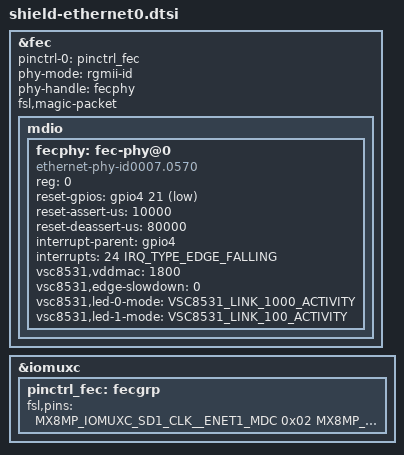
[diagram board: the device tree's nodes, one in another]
// SPDX-License-Identifier: (GPL-2.0+ OR MIT)
/*
 * Copyright 2025 CriticalShift
 */

#include <dt-bindings/net/mscc-phy-vsc8531.h>

&fec {
	pinctrl-names = "default";
	pinctrl-0 = <&pinctrl_fec>;
	phy-mode = "rgmii-id";
	phy-handle = <&fecphy>;
	fsl,magic-packet;
	status = "okay";

	mdio {
		#address-cells = <1>;
		#size-cells = <0>;

		fecphy: fec-phy@0 {
			compatible = "ethernet-phy-id0007.0570", "ethernet-phy-ieee802.3-c22";
			reg = <0>;

			/* Reset handler */
			reset-gpios = <&gpio4 21 GPIO_ACTIVE_LOW>;
			reset-assert-us = <10000>;
			reset-deassert-us = <80000>;

			/* Interrupt handler */
			interrupt-parent = <&gpio4>;
			interrupts = <24 IRQ_TYPE_EDGE_FALLING>;

			/* Microsemi VSC8531 */
			vsc8531,vddmac		= <1800>;
			vsc8531,edge-slowdown	= <0>;
			vsc8531,led-0-mode	= <VSC8531_LINK_1000_ACTIVITY>;
			vsc8531,led-1-mode	= <VSC8531_LINK_100_ACTIVITY>;
		};
	};
};

&iomuxc {
	pinctrl_fec: fecgrp {
		fsl,pins = <
			/* MDIO */
			MX8MP_IOMUXC_SD1_CLK__ENET1_MDC						0x02
			MX8MP_IOMUXC_SD1_CMD__ENET1_MDIO					0x02

			/* RGMII Tx */
			MX8MP_IOMUXC_SD1_DATA1__ENET1_RGMII_TD0				0x16
			MX8MP_IOMUXC_SD1_DATA0__ENET1_RGMII_TD1				0x16
			MX8MP_IOMUXC_SAI1_TXD2__ENET1_RGMII_TD2				0x16
			MX8MP_IOMUXC_SAI1_TXD3__ENET1_RGMII_TD3				0x16
			MX8MP_IOMUXC_SAI1_TXD4__ENET1_RGMII_TX_CTL			0x16
			MX8MP_IOMUXC_SAI1_TXD5__ENET1_RGMII_TXC				0x16

			/* RGMII Rx */
			MX8MP_IOMUXC_SD1_DATA2__ENET1_RGMII_RD0				0x90
			MX8MP_IOMUXC_SD1_DATA3__ENET1_RGMII_RD1				0x90
			MX8MP_IOMUXC_SAI1_RXD6__ENET1_RGMII_RD2				0x90
			MX8MP_IOMUXC_SAI1_RXD7__ENET1_RGMII_RD3				0x90
			MX8MP_IOMUXC_SAI1_TXC__ENET1_RGMII_RXC				0x90
			MX8MP_IOMUXC_SAI1_TXFS__ENET1_RGMII_RX_CTL			0x90

			/* GPIOs */
			MX8MP_IOMUXC_SAI2_RXFS__GPIO4_IO21					0x30 /* RST */
			MX8MP_IOMUXC_SAI2_TXFS__GPIO4_IO24					0x10 /* INT */
		>;
	};
};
